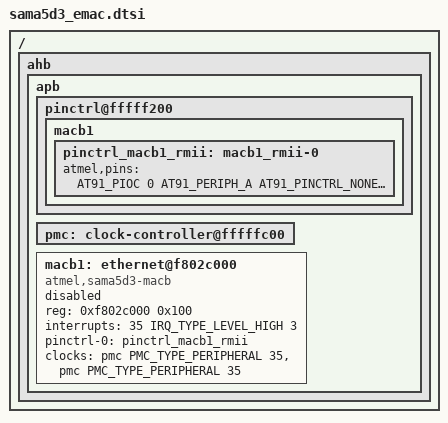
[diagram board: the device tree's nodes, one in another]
#include <dt-bindings/pinctrl/at91.h>
#include <dt-bindings/interrupt-controller/irq.h>
/ {
	ahb {
		apb {
			pinctrl@fffff200 {
				macb1 {
					pinctrl_macb1_rmii: macb1_rmii-0 {
						atmel,pins =
							<AT91_PIOC 0 AT91_PERIPH_A AT91_PINCTRL_NONE	 
							 AT91_PIOC 1 AT91_PERIPH_A AT91_PINCTRL_NONE	 
							 AT91_PIOC 2 AT91_PERIPH_A AT91_PINCTRL_NONE	 
							 AT91_PIOC 3 AT91_PERIPH_A AT91_PINCTRL_NONE	 
							 AT91_PIOC 4 AT91_PERIPH_A AT91_PINCTRL_NONE	 
							 AT91_PIOC 5 AT91_PERIPH_A AT91_PINCTRL_NONE	 
							 AT91_PIOC 6 AT91_PERIPH_A AT91_PINCTRL_NONE	 
							 AT91_PIOC 7 AT91_PERIPH_A AT91_PINCTRL_NONE	 
							 AT91_PIOC 8 AT91_PERIPH_A AT91_PINCTRL_NONE	 
							 AT91_PIOC 9 AT91_PERIPH_A AT91_PINCTRL_NONE>;	 
					};
				};
			};
			pmc: clock-controller@fffffc00 {
			};
			macb1: ethernet@f802c000 {
				compatible = "atmel,sama5d3-macb", "cdns,at91sam9260-macb", "cdns,macb";
				reg = <0xf802c000 0x100>;
				interrupts = <35 IRQ_TYPE_LEVEL_HIGH 3>;
				pinctrl-names = "default";
				pinctrl-0 = <&pinctrl_macb1_rmii>;
				clocks = <&pmc PMC_TYPE_PERIPHERAL 35>, <&pmc PMC_TYPE_PERIPHERAL 35>;
				clock-names = "hclk", "pclk";
				status = "disabled";
			};
		};
	};
};
